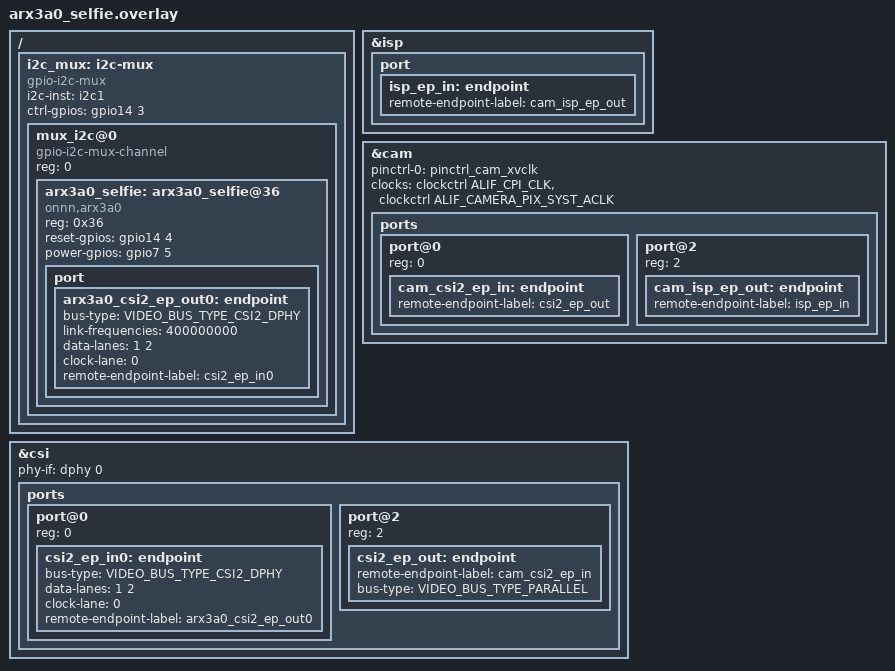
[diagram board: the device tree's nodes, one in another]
/* ARX3A0 Selfie camera sensor + AXI DMA pipeline */

/ {
    i2c_mux: i2c-mux {
	compatible = "gpio-i2c-mux";
	status = "okay";
	#address-cells = <1>;
	#size-cells = <0>;
	i2c-inst = <&i2c1>;
	ctrl-gpios = <&gpio14 3 GPIO_ACTIVE_HIGH>;

	mux_i2c@0 {
		compatible = "gpio-i2c-mux-channel";
		reg = <0>;
		#address-cells = <1>;
		#size-cells = <0>;

		arx3a0_selfie: arx3a0_selfie@36 {
			compatible = "onnn,arx3a0";
			reg = <0x36>;
			reset-gpios = <&gpio14 4 GPIO_ACTIVE_HIGH>;
			power-gpios = <&gpio7 5 GPIO_ACTIVE_HIGH>;
			status = "okay";

			port {
				arx3a0_csi2_ep_out0: endpoint {
				bus-type = <VIDEO_BUS_TYPE_CSI2_DPHY>;
				link-frequencies = <400000000>;
				data-lanes = <1 2>;
				clock-lane = <0>;
				remote-endpoint-label = "csi2_ep_in0";
					};
				};
			};
		};
	};
};

&isp {
	status = "okay";
		port {
			isp_ep_in: endpoint {
			remote-endpoint-label = "cam_isp_ep_out";
			};
		};
};

&cam {
	status = "okay";
	pinctrl-0 = <&pinctrl_cam_xvclk>;
	pinctrl-names = "default";
	clocks = <&clockctrl ALIF_CPI_CLK>, <&clockctrl ALIF_CAMERA_PIX_SYST_ACLK>;
	clock-names = "cam_clk", "pix_clk";

	ports {
		#address-cells = <1>;
		#size-cells = <0>;

		port@0 {
			reg = <0>;
			cam_csi2_ep_in: endpoint {
				remote-endpoint-label = "csi2_ep_out";
			};
		};

		/* ISP Interface */
		port@2 {
			reg = <2>;
			cam_isp_ep_out: endpoint {
				remote-endpoint-label = "isp_ep_in";
			};
		};

	};
};

&csi {
	status = "okay";
	phy-if = <&dphy 0>;

		ports {
			#address-cells = <1>;
			#size-cells = <0>;

			port@0 {
				reg = <0>;
				csi2_ep_in0: endpoint {
					bus-type = <VIDEO_BUS_TYPE_CSI2_DPHY>;
					data-lanes = <1 2>;
					clock-lane = <0>;
					remote-endpoint-label = "arx3a0_csi2_ep_out0";
				};
			};

			port@2 {
				reg = <2>;
				csi2_ep_out: endpoint {
					remote-endpoint-label = "cam_csi2_ep_in";
					bus-type = <VIDEO_BUS_TYPE_PARALLEL>;
					};
				};
			};
};
